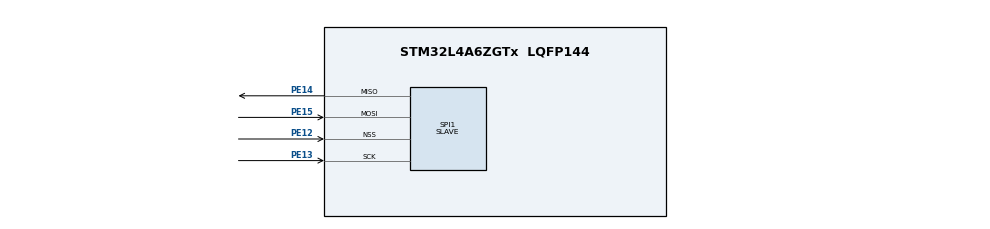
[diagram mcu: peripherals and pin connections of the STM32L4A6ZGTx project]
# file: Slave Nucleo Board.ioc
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Mcu.Family=STM32L4
Mcu.Name=STM32L4A6ZGTx
Mcu.Package=LQFP144
NVIC.PriorityGroup=NVIC_PRIORITYGROUP_4
NVIC.SPI1_IRQn=true\:0\:0\:false\:false\:true\:true\:true
PE12.Mode=NSS_Signal_Hard_Input
PE12.Signal=SPI1_NSS
PE13.Mode=Full_Duplex_Slave
PE13.Signal=SPI1_SCK
PE14.Mode=Full_Duplex_Slave
PE14.Signal=SPI1_MISO
PE15.Mode=Full_Duplex_Slave
PE15.Signal=SPI1_MOSI
ProjectManager.HeapSize=0x200
ProjectManager.StackSize=0x400
ProjectManager.TargetToolchain=EWARM V8.32
RCC.HSE_VALUE=8000000
RCC.HSI48_VALUE=48000000
RCC.HSI_VALUE=16000000
RCC.LSE_VALUE=32768
RCC.MSI_VALUE=4000000
RCC.VCOOutputFreq_Value=32000000
SPI1.DataSize=SPI_DATASIZE_8BIT
SPI1.Direction=SPI_DIRECTION_2LINES
SPI1.Mode=SPI_MODE_SLAVE
SPI1.VirtualNSS=VM_NSSHARD
SPI1.VirtualType=VM_SLAVE
board=custom

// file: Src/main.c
/* USER CODE BEGIN Header */
/**
  ******************************************************************************
  * @file           : main.c
  * @brief          : Main program body
  ******************************************************************************
  * @attention
  *
  * <h2><center>&copy; Copyright (c) 2019 STMicroelectronics.
  * All rights reserved.</center></h2>
  *
  * This software component is licensed by ST under BSD 3-Clause license,
  * the "License"; You may not use this file except in compliance with the
  * License. You may obtain a copy of the License at:
  *                        opensource.org/licenses/BSD-3-Clause
  *
  ******************************************************************************
  */
/* USER CODE END Header */

#include "main.h"
#include "stdio.h"

/* USER CODE BEGIN PD */
#define TXBUFFERSIZE 19
#define RXBUFFERSIZE TXBUFFERSIZE
/* USER CODE END PD */

SPI_HandleTypeDef hspi1;

/* USER CODE BEGIN PV */
uint8_t aTxBuffer[TXBUFFERSIZE] = "Hello from Slave !\n";
uint8_t aRxBuffer[RXBUFFERSIZE];
/* USER CODE END PV */

void SystemClock_Config(void);
static void MX_GPIO_Init(void);
static void MX_SPI1_Init(void);

int main(void)
{

  /* MCU Configuration--------------------------------------------------------*/

  /* Reset of all peripherals, Initializes the Flash interface and the Systick. */
  HAL_Init();

  /* Configure the system clock */
  SystemClock_Config();

  /* Initialize all configured peripherals */
  MX_GPIO_Init();
  MX_SPI1_Init();
  HAL_SPI_Receive_IT(&hspi1, aRxBuffer, RXBUFFERSIZE);
  /* Infinite loop */
  while (1)
  {
//    if (HAL_SPI_Receive_IT(&hspi1, aRxBuffer, RXBUFFERSIZE) != HAL_OK)
//    {
//      Error_Handler();
//    }
//    HAL_Delay(1000);

    /* USER CODE END WHILE */

  }
}

void SystemClock_Config(void)
{
  RCC_OscInitTypeDef RCC_OscInitStruct = {0};
  RCC_ClkInitTypeDef RCC_ClkInitStruct = {0};

  /** Initializes the CPU, AHB and APB busses clocks
  */
  RCC_OscInitStruct.OscillatorType = RCC_OSCILLATORTYPE_MSI;
  RCC_OscInitStruct.MSIState = RCC_MSI_ON;
  RCC_OscInitStruct.MSICalibrationValue = 0;
  RCC_OscInitStruct.MSIClockRange = RCC_MSIRANGE_6;
  RCC_OscInitStruct.PLL.PLLState = RCC_PLL_ON;
  RCC_OscInitStruct.PLL.PLLSource = RCC_PLLSOURCE_MSI;
  RCC_OscInitStruct.PLL.PLLM = 1;
  RCC_OscInitStruct.PLL.PLLN = 40;
  RCC_OscInitStruct.PLL.PLLP = RCC_PLLP_DIV7;
  RCC_OscInitStruct.PLL.PLLQ = RCC_PLLQ_DIV2;
  RCC_OscInitStruct.PLL.PLLR = RCC_PLLR_DIV2;
  if (HAL_RCC_OscConfig(&RCC_OscInitStruct) != HAL_OK)
  {
    Error_Handler();
  }
  /** Initializes the CPU, AHB and APB busses clocks
  */
  RCC_ClkInitStruct.ClockType = RCC_CLOCKTYPE_HCLK|RCC_CLOCKTYPE_SYSCLK
                              |RCC_CLOCKTYPE_PCLK1|RCC_CLOCKTYPE_PCLK2;
  RCC_ClkInitStruct.SYSCLKSource = RCC_SYSCLKSOURCE_MSI;
  RCC_ClkInitStruct.AHBCLKDivider = RCC_SYSCLK_DIV1;
  RCC_ClkInitStruct.APB1CLKDivider = RCC_HCLK_DIV1;
  RCC_ClkInitStruct.APB2CLKDivider = RCC_HCLK_DIV1;

  if (HAL_RCC_ClockConfig(&RCC_ClkInitStruct, FLASH_LATENCY_0) != HAL_OK)
  {
    Error_Handler();
  }
  /** Configure the main internal regulator output voltage
  */
  if (HAL_PWREx_ControlVoltageScaling(PWR_REGULATOR_VOLTAGE_SCALE1) != HAL_OK)
  {
    Error_Handler();
  }
}

static void MX_SPI1_Init(void)
{

  /* SPI1 parameter configuration*/
  hspi1.Instance = SPI1;
  hspi1.Init.Mode = SPI_MODE_SLAVE;
  hspi1.Init.Direction = SPI_DIRECTION_2LINES;
  hspi1.Init.DataSize = SPI_DATASIZE_8BIT;
  hspi1.Init.CLKPolarity = SPI_POLARITY_LOW;
  hspi1.Init.CLKPhase = SPI_PHASE_1EDGE;
  hspi1.Init.NSS = SPI_NSS_HARD_INPUT;
  hspi1.Init.FirstBit = SPI_FIRSTBIT_MSB;
  hspi1.Init.TIMode = SPI_TIMODE_DISABLE;
  hspi1.Init.CRCCalculation = SPI_CRCCALCULATION_DISABLE;
  hspi1.Init.CRCPolynomial = 7;
  hspi1.Init.CRCLength = SPI_CRC_LENGTH_DATASIZE;
  hspi1.Init.NSSPMode = SPI_NSS_PULSE_DISABLE;
  if (HAL_SPI_Init(&hspi1) != HAL_OK)
  {
    Error_Handler();
  }

}

static void MX_GPIO_Init(void)
{

  /* GPIO Ports Clock Enable */
  __HAL_RCC_GPIOE_CLK_ENABLE();

}

/* USER CODE BEGIN 4 */
  void HAL_SPI_RxCpltCallback(SPI_HandleTypeDef * hspi)
  {
    HAL_SPI_Receive_IT(&hspi1, aRxBuffer, RXBUFFERSIZE);
    printf("Reception is correct\n");
  }

/* USER CODE END 4 */

void Error_Handler(void)
{
  /* USER CODE BEGIN Error_Handler_Debug */
  /* User can add his own implementation to report the HAL error return state */
      printf("error while reception \n");

  /* USER CODE END Error_Handler_Debug */
}

/************************ (C) COPYRIGHT STMicroelectronics *****END OF FILE****/
